# SF32LB55x register map
File version: 1.0
CPU: CM33 r0p1, little endian, MPU, FPU, 3 interrupt priority bits
Registers are 32-bit, read-write, reset 0x0 unless marked. A register's access mark holds for its fields unless they carry their own. Offsets are from the block's base; [hi:lo] are bit positions.

## TSEN
Base 0x4005A000
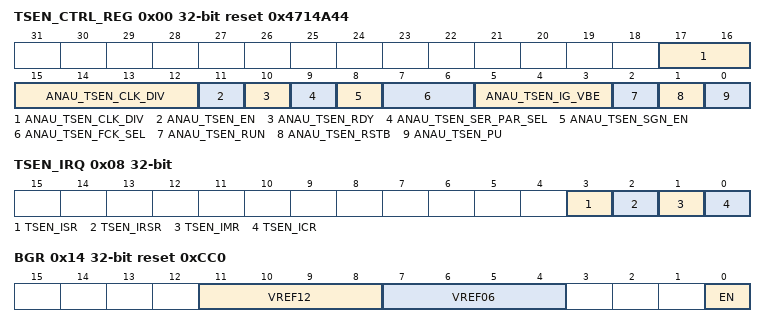
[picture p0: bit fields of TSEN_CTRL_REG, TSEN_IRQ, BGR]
0x00 TSEN_CTRL_REG reset 0x4714A44 — TSEN Analog Control Register
  [17:12] ANAU_TSEN_CLK_DIV — gen tsen clk by divide pclk by anau_tsen_clk_div
  [11] ANAU_TSEN_EN — Enable tsen digital module
  [10] ANAU_TSEN_RDY — tsen ready
  [9] ANAU_TSEN_SER_PAR_SEL — serial-parallel output selection
  [8] ANAU_TSEN_SGN_EN — signature-mode enable
  [7:6] ANAU_TSEN_FCK_SEL — select internal clock frequency
  [5:3] ANAU_TSEN_IG_VBE — bias current selection to tune vba
  [2] ANAU_TSEN_RUN — enable tsen run
  [1] ANAU_TSEN_RSTB — resetb for tsen
  [0] ANAU_TSEN_PU — power up tsen
0x04 TSEN_RDATA — Tsen Read Data
  [11:0] TSEN_RDATA
0x08 TSEN_IRQ
  [3] TSEN_ISR, [2] TSEN_IRSR, [1] TSEN_IMR, [0] TSEN_ICR
0x10 ANAU_ANA_TP — Tsen IRQ Register
  [0] ANAU_IARY_EN
0x14 BGR reset 0xCC0 — Bandgap registers
  [11:8] VREF12 — select VREF 1.2V
  [7:4] VREF06 — select VREF 0.6V
  [0] EN — Bandgap enable

## LPSYS_GPIO
Base 0x50040000
0x00 DIR0 — Data Input Register
  [31:0] IN — GPIO[31:0] input value
0x04 DOR0 — Data Output Register
  [31:0] OUT — GPIO[31:0] output value if output enabled
0x08 DOER0 — Data Output Enable Register
  [31:0] DOE — GPIO[31:0] output enable
0x0C OESR0 — Data Output Enable Set Register
  [31:0] OES — set 1 to enable output of corresponding GPIO[31:0]
0x10 OECR0 — Data Output Enable Clear Register
  [31:0] OEC — set 1 to disable output of corresponding GPIO[31:0]
0x14 IER0 — Interrupt Enable Register
  [31:0] IER — GPIO[31:0] interrupt enable
0x18 IESR0 — Interrupt Enable Set Register
  [31:0] IES — set 1 to enable interrupt of corresponding GPIO[31:0]
0x1C IECR0 — Interrupt Enable Clear Register
  [31:0] IEC — set 1 to disable interrupt of corresponding GPIO[31:0]
0x20 ITR0 — Interrupt Type Register
  [31:0] ITR — GPIO[31:0] interrupt type
0x24 ITSR0 — Interrupt Type Set Register
  [31:0] ITS — set 1 for edge-sensitive interrupt mode of corresponding GPIO[31:0]
0x28 ITCR0 — Interrupt Type Clear Register
  [31:0] ITC — set 1 for level-sensitive interrupt mode of corresponding GPIO[31:0]
0x2C IPSR0 — Interrupt Polarity Set Register
  [31:0] IPS — set 1 for rising edge in edge mode, or high level in level mode of corresponding GPIO[31:0]
0x30 IPCR0 — Interrupt Polarity Clear Register
  [31:0] IPC — set 1 for falling edge in edge mode, or low level in level mode of corresponding GPIO[31:0]
0x34 ISR0 — Interrupt Status Register
  [31:0] IS — Interrupt status. Write 1 will clear interrupt status of corresponding GPIO[31:0]
0x38 DIR1 — Data Input Register
  [16:0] IN — GPIO[48:32] input value
0x3C DOR1 — Data Output Register
  [16:0] OUT — GPIO[48:32]output value if output enabled
0x40 DOER1 — Data Direction Register
  [16:0] DOE — GPIO[48:32] output enable
0x44 OESR1 — Data Output Enable Set Register
  [16:0] OES — set 1 to enable output of corresponding GPIO[48:32]
0x48 OECR1 — Data Output Enable Clear Register
  [16:0] OEC — set 1 to disable output of corresponding GPIO[48:32]
0x4C IER1 — Interrupt Enable Register
  [16:0] IER — GPIO[48:32] interrupt enable
0x50 IESR1 — Interrupt Enable Set Register
  [16:0] IES — set 1 to enable interrupt of corresponding GPIO[48:32]
0x54 IECR1 — Interrupt Enable Clear Register
  [16:0] IEC — set 1 to disable interrupt of corresponding GPIO[48:32]
0x58 ITR1 — Interrupt Type Register
  [16:0] ITR — GPIO[48:32] interrupt type
0x5C ITSR1 — Interrupt Type Set Register
  [16:0] ITS — set 1 for edge-sensitive interrupt mode of corresponding GPIO[48:32]
0x60 ITCR1 — Interrupt Type Clear Register
  [16:0] ITC — set 1 for level-sensitive interrupt mode of corresponding GPIO[48:32]
0x64 IPSR1 — Interrupt Polarity Set Register
  [16:0] IPS — set 1 for rising edge in edge mode, or high level in level mode of corresponding GPIO[48:32]
0x68 IPCR1 — Interrupt Polarity Clear Register
  [16:0] IPC — set 1 for falling edge in edge mode, or low level in level mode of corresponding GPIO[48:32]
0x6C ISR1 — Interrupt Status Register
  [16:0] IS — Interrupt status. Write 1 will clear interrupt status of corresponding GPIO[48:32]
